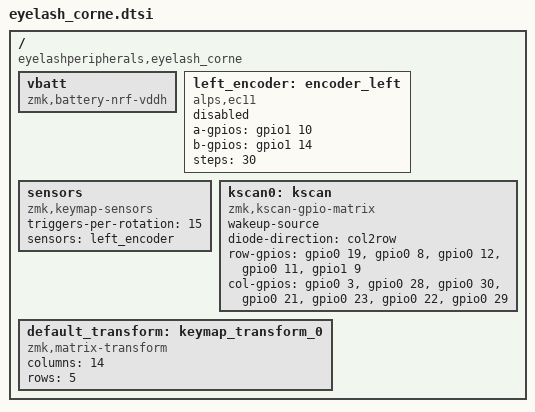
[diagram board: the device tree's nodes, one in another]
/*
 * Shared keyboard definitions for Eyelash Corne
 * (NO SoC, NO USB, NO flash, NO pinctrl)
 */

#include <dt-bindings/led/led.h>
#include <dt-bindings/zmk/matrix_transform.h>

/ {
    compatible = "eyelashperipherals,eyelash_corne";

    vbatt: vbatt {
        compatible = "zmk,battery-nrf-vddh";
    };

    left_encoder: encoder_left {
        compatible = "alps,ec11";
        a-gpios = <&gpio1 10 (GPIO_ACTIVE_HIGH | GPIO_PULL_UP)>;
        b-gpios = <&gpio1 14 (GPIO_ACTIVE_HIGH | GPIO_PULL_UP)>;
        steps = <30>;
        status = "disabled";
    };

    sensors {
        compatible = "zmk,keymap-sensors";
        triggers-per-rotation = <15>;
        sensors = <&left_encoder>;
    };

    kscan0: kscan {
        compatible = "zmk,kscan-gpio-matrix";
        wakeup-source;
        diode-direction = "col2row";

        row-gpios =
            <&gpio0 19 (GPIO_ACTIVE_HIGH | GPIO_PULL_DOWN)>,
            <&gpio0 8  (GPIO_ACTIVE_HIGH | GPIO_PULL_DOWN)>,
            <&gpio0 12 (GPIO_ACTIVE_HIGH | GPIO_PULL_DOWN)>,
            <&gpio0 11 (GPIO_ACTIVE_HIGH | GPIO_PULL_DOWN)>,
            <&gpio1 9  (GPIO_ACTIVE_HIGH | GPIO_PULL_DOWN)>;

        col-gpios =
            <&gpio0 3  GPIO_ACTIVE_HIGH>,
            <&gpio0 28 GPIO_ACTIVE_HIGH>,
            <&gpio0 30 GPIO_ACTIVE_HIGH>,
            <&gpio0 21 GPIO_ACTIVE_HIGH>,
            <&gpio0 23 GPIO_ACTIVE_HIGH>,
            <&gpio0 22 GPIO_ACTIVE_HIGH>,
            <&gpio0 29 GPIO_ACTIVE_HIGH>;
    };

    default_transform: keymap_transform_0 {
        compatible = "zmk,matrix-transform";
        columns = <14>;
        rows = <5>;
        /* map stays here */
    };
};
